# EFR32MG24A110F1024IM48 register map
Vendor: Silicon Labs; Series: EFR32; File version: B
Registers are 32-bit, read-write, reset 0x0 unless marked. A register's access mark holds for its fields unless they carry their own. Offsets are from the block's base; [hi:lo] are bit positions; {n}, {i} and the like mark numbered series; 'fields as' and 'values as' point back to an identical list.

## MODEM_S (part 1 of 2) — MODEM_S Registers
Base 0xA8014000
Same registers: MODEM_NS 0xB8014000
0x00 IPVERSION ro reset 0x3
0x04 EN
  [0] EN — Enable peripheral clock to this module
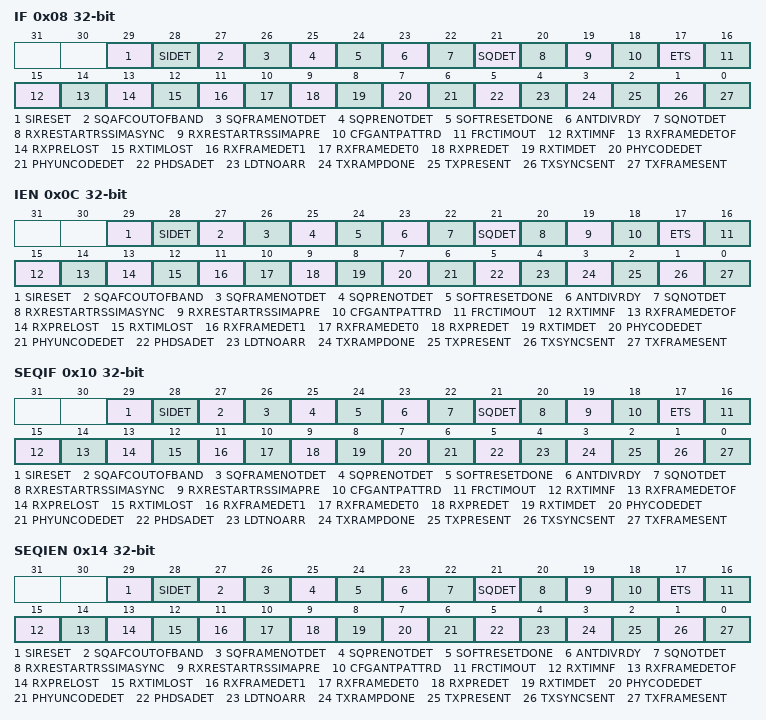
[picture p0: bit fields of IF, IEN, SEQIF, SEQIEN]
0x08 IF
  [29] SIRESET — Signal identifier reset
  [28] SIDET — Signal identified
  [27] SQAFCOUTOFBAND
  [26] SQFRAMENOTDET — SQ Not Detect
  [25] SQPRENOTDET — SQ Not Detect
  [24] SOFTRESETDONE
  [23] ANTDIVRDY — RSSI and CORR data Ready
  [22] SQNOTDET — SQ Not Detect
  [21] SQDET — SQ Detect
  [20] RXRESTARTRSSIMASYNC — RX restart using RSSI MA filter
  [19] RXRESTARTRSSIMAPRE — RX restart using RSSI MA filter
  [18] CFGANTPATTRD — cfg
  [17] ETS — Early Time Stamp detect
  [16] FRCTIMOUT — DEMOD-FRC req/ack timeout
  [15] RXTIMNF — Timing not found
  [14] RXFRAMEDETOF — Frame detection overflow
  [13] RXPRELOST — Preamble lost
  [12] RXTIMLOST — Timing lost
  [11] RXFRAMEDET1 — Frame with sync-word 1 detected
  [10] RXFRAMEDET0 — Frame with sync-word 0 detected
  [9] RXPREDET — Preamble detected
  [8] RXTIMDET — Timing detected
  [7] PHYCODEDET — CONCURRENT CODED PHY DET
  [6] PHYUNCODEDET — CONCURRENT UNCODED PHY DET
  [5] PHDSADET — PHASE DSA DETECT
  [4] LDTNOARR — No signal Detected in LDT
  [3] TXRAMPDONE — Mod ramper idle
  [2] TXPRESENT — Preamble sent
  [1] TXSYNCSENT — Sync word sent
  [0] TXFRAMESENT — Frame sent
0x0C IEN
  [29] SIRESET — Signal identifier reset
  [28] SIDET — Signal Identified
  [27] SQAFCOUTOFBAND
  [26] SQFRAMENOTDET — SQ Not Detected
  [25] SQPRENOTDET — SQ Not Detected
  [24] SOFTRESETDONE
  [23] ANTDIVRDY — RSSI and CORR data Ready
  [22] SQNOTDET — SQ Not Detected
  [21] SQDET — SQ Detected
  [20] RXRESTARTRSSIMASYNC — RX restart using RSSI MA filter
  [19] RXRESTARTRSSIMAPRE — RX restart using RSSI MA filter
  [18] CFGANTPATTRD
  [17] ETS — Early Time Stamp detect
  [16] FRCTIMOUT — DEMOD-FRC req/ack timeout
  [15] RXTIMNF — Timing not found
  [14] RXFRAMEDETOF — Frame detection overflow
  [13] RXPRELOST — Preamble lost
  [12] RXTIMLOST — Timing lost
  [11] RXFRAMEDET1 — Frame with sync-word 1 detected
  [10] RXFRAMEDET0 — Frame with sync-word 0 detected
  [9] RXPREDET — Preamble detected
  [8] RXTIMDET — Timing detected
  [7] PHYCODEDET — CONCURRENT CODED PHY DET
  [6] PHYUNCODEDET — CONCURRENT UNCODED PHY DET
  [5] PHDSADET — PHASE DSA DETECT
  [4] LDTNOARR — No signal Detected in LDT
  [3] TXRAMPDONE — Mod ramper idle
  [2] TXPRESENT — Preamble sent
  [1] TXSYNCSENT — Sync word sent
  [0] TXFRAMESENT — Frame sent
0x10 SEQIF
  [29] SIRESET — Signal identifier reset
  [28] SIDET — Signal identified
  [27] SQAFCOUTOFBAND
  [26] SQFRAMENOTDET — SQ NOT Detected
  [25] SQPRENOTDET — SQ NOT Detected
  [24] SOFTRESETDONE
  [23] ANTDIVRDY — RSSI and CORR data Ready
  [22] SQNOTDET — SQ NOT Detected
  [21] SQDET — SQ Detected
  [20] RXRESTARTRSSIMASYNC — RX restart using RSSI MA filter
  [19] RXRESTARTRSSIMAPRE — RX restart using RSSI MA filter
  [18] CFGANTPATTRD
  [17] ETS — Early timestamp
  [16] FRCTIMOUT — DEMOD-FRC req/ack timeout
  [15] RXTIMNF — Timing not found
  [14] RXFRAMEDETOF — Frame detection overflow
  [13] RXPRELOST — Preamble lost
  [12] RXTIMLOST — Timing lost
  [11] RXFRAMEDET1 — Frame with sync-word 1 detected
  [10] RXFRAMEDET0 — Frame with sync-word 0 detected
  [9] RXPREDET — Preamble detected
  [8] RXTIMDET — Timing detected
  [7] PHYCODEDET — CONCURRENT CODED PHY DET
  [6] PHYUNCODEDET — CONCURRENT UNCODED PHY DET
  [5] PHDSADET — PHASE DSA DETECT
  [4] LDTNOARR — No signal Detected in LDT
  [3] TXRAMPDONE — Mod ramper idle
  [2] TXPRESENT — Preamble sent
  [1] TXSYNCSENT — Sync word sent
  [0] TXFRAMESENT — Frame sent
0x14 SEQIEN
  [29] SIRESET — Signal identifier reset
  [28] SIDET — Signal Identified
  [27] SQAFCOUTOFBAND
  [26] SQFRAMENOTDET — SQ Not DET
  [25] SQPRENOTDET — SQ Not DET
  [24] SOFTRESETDONE
  [23] ANTDIVRDY — RSSI and CORR data Ready
  [22] SQNOTDET
  [21] SQDET
  [20] RXRESTARTRSSIMASYNC — RX restart using RSSI MA filter
  [19] RXRESTARTRSSIMAPRE — RX restart using RSSI MA filter
  [18] CFGANTPATTRD
  [17] ETS — Early time stamp
  [16] FRCTIMOUT — DEMOD-FRC req/ack timeout
  [15] RXTIMNF — Timing not found
  [14] RXFRAMEDETOF — Frame detection overflow
  [13] RXPRELOST — Preamble lost
  [12] RXTIMLOST — Timing lost
  [11] RXFRAMEDET1 — Frame with sync-word 1 detected
  [10] RXFRAMEDET0 — Frame with sync-word 0 detected
  [9] RXPREDET — Preamble detected
  [8] RXTIMDET — Timing detected
  [7] PHYCODEDET — CONCURRENT CODED PHY DET
  [6] PHYUNCODEDET — CONCURRENT UNCODED PHY DET
  [5] PHDSADET — PHASE DSA DETECT
  [4] LDTNOARR — No signal Detected in LDT
  [3] TXRAMPDONE — Mod ramper idle
  [2] TXPRESENT — Preamble sent
  [1] TXSYNCSENT — Sync word sent
  [0] TXFRAMESENT — Frame sent
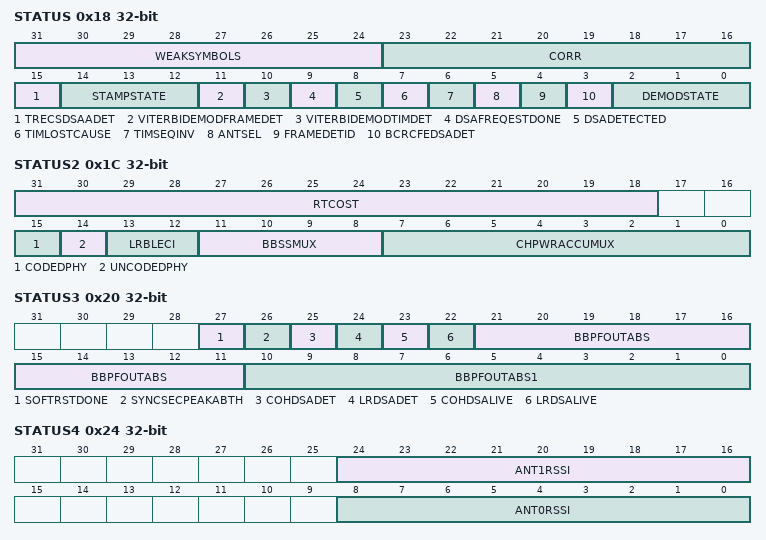
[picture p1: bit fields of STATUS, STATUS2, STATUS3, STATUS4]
0x18 STATUS ro
  [31:24] WEAKSYMBOLS
  [23:16] CORR — Correlation
  [15] TRECSDSAADET — TRECS DSA DETECTION
  [14:12] STAMPSTATE — BLE Viterbi Demod Timing Stamp
  [11] VITERBIDEMODFRAMEDET — Viterbi Demod frame detected
  [10] VITERBIDEMODTIMDET — Viterbi Demod timing detected
  [9] DSAFREQESTDONE — DSA frequency estimation complete
  [8] DSADETECTED — PHASE-DSA detected
  [7] TIMLOSTCAUSE — Timing Lost Cause
    0=LOWCORR (Timing lost during Preamble Search or due to low correlation value during Frame Search.); 1=TIMEOUT (Timing lost due to incorrect symbols detected during Frame Search.)
  [6] TIMSEQINV — Timing Sequence Inverted
  [5] ANTSEL — Selected Antenna
    0=ANTENNA0 (Antenna 0 is selected (ANT0 = 1 and ANT1 = 0).); 1=ANTENNA1 (Antenna 1 is selected (ANT0 = 0 and ANT1 = 1).)
  [4] FRAMEDETID — Frame Detected ID
    0=FRAMEDET0 (Last frame was detected with sync word defined in SYNC0.); 1=FRAMEDET1 (Last frame was detected with sync word defined in SYNC1.)
  [3] BCRCFEDSADET — BCR CFE DSA DETECTION
  [2:0] DEMODSTATE
    0=OFF (Off state); 1=TIMINGSEARCH; 2=PRESEARCH (Preamble search); 3=FRAMESEARCH; 4=RXFRAME (Payload Detection); 5=FRAMEDETMODE0 (Timing search with sliding window (FDM0))
0x1C STATUS2 ro
  [31:18] RTCOST — phase demod real time cost
  [15] CODEDPHY — CODED PHY DET
  [14] UNCODEDPHY — UNCODED PHY DET
  [13:12] LRBLECI — RXed packet's LR BLE coding indicator
    0=LR125k (FEC block 2 coded using C=8, 125kbps); 1=LR500k (FEC block 2 coded using C=2, 500kbps)
  [11:8] BBSSMUX — Actual Baseband Signal Selection
  [7:0] CHPWRACCUMUX — Channel power
0x20 STATUS3 ro
  [27] SOFTRSTDONE — Soft reset done
  [26] SYNCSECPEAKABTH — SYNC second peak above threshold
  [25] COHDSADET — DSA prefilter above CDTH
  [24] LRDSADET — DSA prefilter above LRSPIKETHD
  [23] COHDSALIVE — COHDSA Prefilter above CDTH
  [22] LRDSALIVE — BLRDSA Prefilter above LRSPIKETHD
  [21:11] BBPFOUTABS — Pre-filter Correlation Output for BLR
  [10:0] BBPFOUTABS1 — Pre-filter Correlation Output
0x24 STATUS4 ro
  [24:16] ANT1RSSI — ANT1 RSSI value
  [8:0] ANT0RSSI — ANT0 RSSI value
0x28 STATUS5 ro
  [8:0] RXRESTARTMAFLTDOUT — RSSI MA filter output value
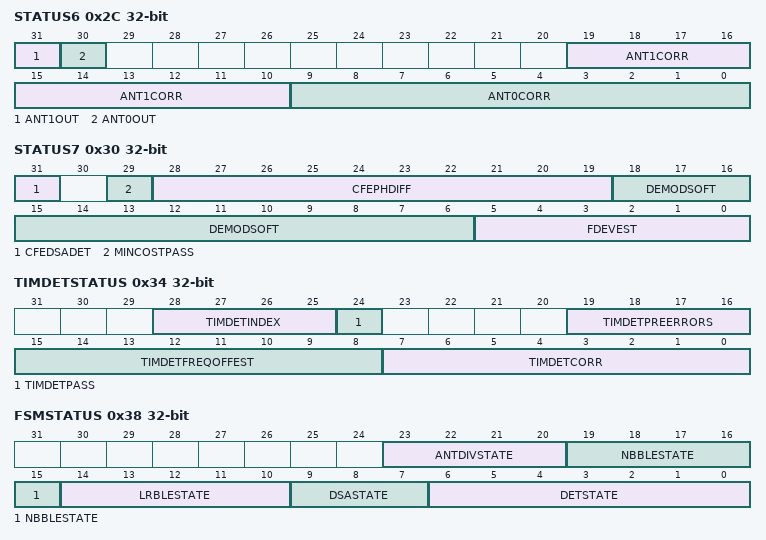
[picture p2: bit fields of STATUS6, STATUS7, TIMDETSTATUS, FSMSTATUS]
0x2C STATUS6 ro
  [31] ANT1OUT — ANT1 OUTPUT
  [30] ANT0OUT — ANT0 OUTPUT
  [19:10] ANT1CORR — ANT1 Correlation value
  [9:0] ANT0CORR — ANT0 Correlation value
0x30 STATUS7 ro
  [31] CFEDSADET — CFE-based DSA Detection
  [29] MINCOSTPASS — Min.COST Threshold Pass
  [28:19] CFEPHDIFF — CEF PHASE DIFF INPUT
  [18:6] DEMODSOFT — PHASE DEMOD Soft code
  [5:0] FDEVEST — Frequency Deviation Error Estimation
0x34 TIMDETSTATUS ro
  [28:25] TIMDETINDEX — Timing detection index
  [24] TIMDETPASS — Timing detection pass
  [19:16] TIMDETPREERRORS — Preamble errors
  [15:8] TIMDETFREQOFFEST — Frequency offset estimate
  [7:0] TIMDETCORR — Correlation value
0x38 FSMSTATUS ro
  [23:20] ANTDIVSTATE — Antenna diversity control state
    0=IDLE (Idle state); 1=FIRST_ANT0 (First ANT0 selection); 2=FIRST_ANT1 (First ANT1 selection); 3=TIMSEARCH_ANT0 (Timing search on ANT0); 4=TIMSEARCH_ANT1 (Timing search on ANT1); 5=TIMDET_ANT0 (Check ANT1 after timing detecton ANT0); 6=TIMDET_ANT1 (Check ANT0 after timing detecton ANT1); 7=EVALUATE (Evaluate and select better antenna); 8=TIMSEARCH_SELECTED (Searching on better antenna); 9=TIMDET_SELECTED (Selected better antenna); 10=REPEAT_ANT0; 11=REPEAT_ANT1; 15=MANUAL (Manual mode)
  [19:15] NBBLESTATE — Demodulator Narrow-band BLE FSM state
    0=IDLE (IDLE state); 1=VTINITI; 2=ADDRNXT; 3=INICOST; 4=CALCCOST; 5=INITALACQU; 6=INITALCOSTCALC; 7=MINCOSTCALC; 8=FREQACQU; 9=FREQACQUDONE; 10=TIMINGACQUEARLY; 11=TIMINGACQUCURR; 12=TIMINGACQULATE; 13=TIMINGACQUDONE; 14=VIRTBIINIT0; 15=VIRTBIINIT1; 16=VIRTBIRXSYNC; 17=VIRTBIRXPAYLOAD; 18=HARDRXSYNC; 19=HARDXPAYLOAD (HARD_RXPAYLOAD); 20=TRACKFREQ; 21=TRACKTIMEARLY; 22=TRACKTIMCURR; 23=TRACKTIMLATE; 24=TRACKDONE; 25=TRACKDECISION; 26=STOP; 27=WAITACK; 28=DEBUG
  [14:10] LRBLESTATE — Demodulator long-range BLE FSM state
    0=IDLE (IDLE state); 1=CLEANUP; 2=CORRCOE; 3=WAITLRDSA; 4=MAXCORR; 5=WAITRDY; 6=FEC1DATA; 7=FEC1ACK; 8=PAUSE; 9=FEC2DATA; 10=FEC2ACK; 11=TRACKCUR; 12=TRACKEAR; 13=TRACKLAT; 14=TRACKDONE; 15=TDECISION; 16=STOP
  [9:7] DSASTATE — Demodulator DSA FSM state
    0=IDLE (IDLE state); 1=ARRIVALCHK (Arrival Check); 2=STATUSCHK (Status Check); 3=SAMPPW; 4=WAITPWRUP; 5=WAITDSALO; 6=WAITABORT; 7=STOP
  [6:0] DETSTATE — Detection FSM state
    0=OFF (Off state); 10=TIMINGSEARCH; 20=PRESEARCH (Preamble search); 30=FRAMESEARCH; 40=RXFRAME (Payload Detection); 50=FRAMEDETMODE0 (Timing search with sliding window (FDM0))
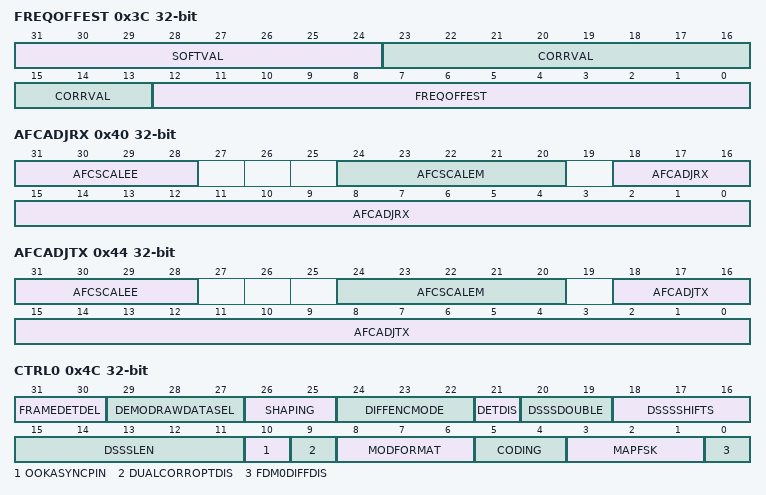
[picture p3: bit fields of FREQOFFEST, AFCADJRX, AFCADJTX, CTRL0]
0x3C FREQOFFEST ro
  [31:24] SOFTVAL — Soft detection value
  [23:13] CORRVAL — Correlation value
  [12:0] FREQOFFEST — Frequency offset estimate
0x40 AFCADJRX
  [31:28] AFCSCALEE — AFC scaling exponent
  [24:20] AFCSCALEM — AFC scaling mantissa
  [18:0] AFCADJRX ro — AFC adjustment for RX
0x44 AFCADJTX
  [31:28] AFCSCALEE — AFC scaling exponent
  [24:20] AFCSCALEM — AFC scaling mantissa
  [18:0] AFCADJTX ro — AFC adjustment for TX
0x48 MIXCTRL
  [4] DIGIQSWAPEN — Digital I/Q swap enable
0x4C CTRL0
  [31:30] FRAMEDETDEL — FRAMEDET delay
    0=DEL0 (No delay); 1=DEL8 (8 baud delay); 2=DEL16 (16 baud delay); 3=DEL32 (32 baud delay)
  [29:27] DEMODRAWDATASEL — Demod raw data select
    0=DIS (Disabled.); 1=ENTROPY (1-bit entropy source extracted from the RF receive chain, to be used for random number generation.); 2=ADC (2 * 3-bit I and Q ADC data.); 3=FILTLSB (2 * 16-bit I and Q channel filtered data downmixed to zero-IF. The receive signal chain has 19 bits dynamic range at this point, and the FILTLSB setting outputs the 16 least significant bits (with saturation).); 4=FILTMSB (2 * 16-bit I and Q channel filtered data downmixed to zero-IF. The receive signal chain has 19 bits dynamic range at this point, and the FILTMSB setting outputs the 16 most significant bits (with truncation).); 5=FILTFULL (2 * 19-bit I and Q channel filtered data downmixed to zero-IF. The FILTFULL option will output all 19 bits of dynamic range, sign extended to 32 bits.); 6=FREQ (8-bit received frequency data (or logarithmic amplitude for ASK/OOK).); 7=DEMOD (8-bit demodulated data (freq/amp/phase). When coherent detection is enabled, only the in-phase component is selected.)
  [26:25] SHAPING — Shaping filter
    0=DISABLED (Filter disabled.); 1=ODDLENGTH (Filter has odd length. Filter uses coefficients 0,1,2,3,4,5,6,7,8,7,6,5,4,3,2,1,0.); 2=EVENLENGTH (Filter has even length. Filter uses coefficients 0,1,2,3,4,5,6,7,7,6,5,4,3,2,1,0.); 3=ASYMMETRIC (Filter has asymmetrical coefficients. Filter uses coefficients 0,1,2,3,4,5,6,7.)
  [24:22] DIFFENCMODE — Differential encoding mode
    0=DIS (Differential Encoding is disabled.); 1=RR0 (Transmit the XOR-ed value of the Raw symbol and the last Raw symbol. Initial Raw symbol is 0.); 2=RE0 (Transmit the XOR-ed value of the Raw symbol and the last Encoded symbol. Initial Encoded symbol is 0.); 3=RR1 (Transmit the XOR-ed value of the Raw symbol and the last Raw symbol. Initial Raw symbol is 1.); 4=RE1 (Transmit the XOR-ed value of the Raw symbol and the last Encoded symbol. Initial Encoded symbol is 1.)
  [21] DETDIS — Detection disable
  [20:19] DSSSDOUBLE
    0=DIS (Doubling is disabled.); 1=INV (Doubling is enabled by using inverted symbols.); 2=CONJ (Doubling is enabled by using complex conjugated symbols.)
  [18:16] DSSSSHIFTS
    0=NOSHIFT (No symbols are defined by shifting.); 1=SHIFT1 (Next symbol generated by 1 cyclic shift.); 2=SHIFT2 (Next symbol generated by 2 cyclic shifts.); 3=SHIFT4 (Next symbol generated by 4 cyclic shifts.); 4=SHIFT8 (Next symbol generated by 8 cyclic shifts.); 5=SHIFT16 (Next symbol generated by 16 cyclic shifts.)
  [15:11] DSSSLEN — DSSS length
  [10] OOKASYNCPIN — OOK asynchronous pin mode
  [9] DUALCORROPTDIS — Dual Correlation Optimization Disable
  [8:6] MODFORMAT — Modulation format
    0=FSK2 (Frequency Shift Keying with 2 symbols); 1=FSK4 (Frequency Shift Keying with 4 symbols); 2=BPSK (Binary Phase Shift Keying); 3=DBPSK (Differentially encoded Binary Phase Shift Keying); 4=OQPSK (Half Sine Shaped Offset Quadrature Phase Shift Keying); 5=MSK (Minimum Shift Keying); 6=OOKASK (On Off Keying and Amplitude Shift Keying)
  [5:4] CODING — Symbol coding
    0=NRZ (Non Return to Zero); 1=MANCHESTER (Manchester Coding); 2=DSSS (Direct Sequence Spread Spectrum); 3=LINECODE (Line code. Maps 0 to 0011 symbol and 1 to 1100 symbols)
  [3:1] MAPFSK — Mapping of FSK symbols
    0=MAP0 (4FSK: Symbol 11, 10, 00, 01 for decreasing frequency. 2FSK/MSK/ASK/OOK: Symbol 1 is high/positive frequency or high amplitude, symbol 0 is low/negative frequency or low amplitude.); 1=MAP1 (4FSK: Symbol 01, 00, 10, 11 for decreasing frequency. 2FSK/MSK/ASK/OOK: Symbol 0 is high/negative frequency or high amplitude, symbol 1 is low/negative frequency or low amplitude.); 2=MAP2 (4FSK: Symbol 10, 11, 01, 00 for decreasing frequency. 2FSK/MSK/ASK/OOK: Undefined.); 3=MAP3 (4FSK: Symbol 00, 01, 11, 10 for decreasing frequency. 2FSK/MSK/ASK/OOK: Undefined.); 4=MAP4 (4FSK: Symbol 11, 01, 00, 10 for decreasing frequency. 2FSK/MSK/ASK/OOK: Undefined.); 5=MAP5 (4FSK: Symbol 10, 00, 01, 11 for decreasing frequency. 2FSK/MSK/ASK/OOK: Undefined.); 6=MAP6 (4FSK: Symbol 01, 11, 10, 00 for decreasing frequency. 2FSK/MSK/ASK/OOK: Undefined.); 7=MAP7 (4FSK: Symbol 00, 10, 11, 01 for decreasing frequency. 2FSK/MSK/ASK/OOK: Undefined.)
  [0] FDM0DIFFDIS — Frame Detection Mode 0 disable
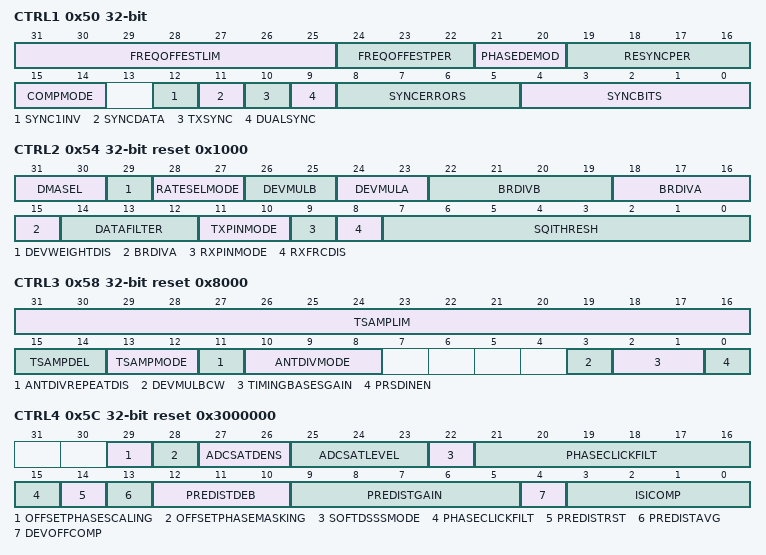
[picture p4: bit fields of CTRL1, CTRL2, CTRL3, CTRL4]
0x50 CTRL1
  [31:25] FREQOFFESTLIM — Frequency offset limit
  [24:22] FREQOFFESTPER — Frequency offset estimation period
  [21:20] PHASEDEMOD — Phase demodulation
    0=BDD (Bit Differential Detection.); 1=MBDD (Multibit Differential Detection.); 2=COH (Coherent Detection.)
  [19:16] RESYNCPER — Resync period
  [15:14] COMPMODE — Compensation mode
    0=DIS (Compensation is disabled.); 1=PRELOCK (Compensation locks when preamble is detected.); 2=FRAMELOCK (Compensation locks when frame is detected.); 3=NOLOCK (Compensation is always running)
  [12] SYNC1INV — SYNC1 invert.
  [11] SYNCDATA
    0=DISABLED (SYNC is not part of transmit payload. Modulator adds SYNC in transmit.); 1=ENABLED (SYNC is part of transmit payload. Modulator does not add SYNC in transmit.)
  [10] TXSYNC — Transmit sync word.
    0=SYNC0 (Modulator transmits SYNC0.); 1=SYNC1 (Modulator transmits SYNC1.)
  [9] DUALSYNC — Dual sync words.
    0=DISABLED (Demodulator only searches for SYNC0.); 1=ENABLED (Demodulator searches for SYNC0 and SYNC1 in parallel.)
  [8:5] SYNCERRORS — Maximum number of sync errors
  [4:0] SYNCBITS — Number of sync-word bits
0x54 CTRL2 reset 0x1000
  [31:30] DMASEL — DMA select.
    0=SOFT (SOFTVAL field); 1=CORR (CORRVAL field); 2=FREQOFFEST; 3=POE
  [29] DEVWEIGHTDIS — Deviation weighting disable.
  [28:27] RATESELMODE — Rate select mode
    0=NOCHANGE (No rate change. BRDIVA/DEVMULA is used for entire frame.); 1=PAYLOAD (Change rate for payload. BRDIVA/DEVMULA is used for header and BRDIVB/DEVMULB is used for payload.); 2=FRC (FRC selects between BRDIVA/DEVMULA and BRDIVB/DEVMULB for each symbol in the payload. Header uses BRDIVA/DEVMULA.); 3=SYNC (The configured/detected syncword decides the settings used for the payload. SYNC0 uses BRDIVA/DEVMULA and SYNC1 uses BRDIVB/DEVMULB. Header uses BRDIVA/DEVMULA.)
  [26:25] DEVMULB — Deviation multiplication factor B
  [24:23] DEVMULA — Deviation multiplication factor A
  [22:19] BRDIVB — Baudrate division factor B
  [18:15] BRDIVA — Baudrate division factor A
  [14:12] DATAFILTER
    0=DISABLED (Datafilter disabled); 1=SHORT (Short datafilter enabled. 2*RXBRFRAC should be more than 3.); 2=MEDIUM (Medium datafilter enabled. 2*RXBRFRAC should be more than 4.); 3=LONG (Long datafilter enabled. 2*RXBRFRAC should be more than 5.); {v}=LEN{v+2} (Datafilter with length {v+2} enabled. 2*RXBRFRAC should be more than {v+2}.) (v=4..7)
  [11:10] TXPINMODE — Transmit pin mode
    0=OFF (Pinmode is turned off. Data is gathered from FRC. DOUT/DCLK clocks out transmitted data.); 1=MFM (Pinmode is turned off. Multi-Level FM Data is gathered from FRC. No support for frame handling nor coding); 2=ASYNCHRONOUS (DIN/PRS controls transmitted baud directly. DCLK is set to 0. No support for frame handling nor coding. Only 2-FSK and OOK/ASK can be used.); 3=SYNCHRONOUS (DIN/PRS is sampled on the rising edge of DCLK and used as payload. Frame handling and coding is supported. Only setups with 1 bit per symbol is supported.)
  [9] RXPINMODE — Receive pin mode
    0=SYNCHRONOUS (Detected payload bits are clocked out on DOUT. Only setups with 1 bit per symbol are supported.); 1=ASYNCHRONOUS (DOUT is continuously providing the sign of the detected frequency deviation before offset compensation. Only 2/4-FSK is supported.)
  [8] RXFRCDIS — Receive FRC disable
  [7:0] SQITHRESH — Signal Quality Indicator threshold
0x58 CTRL3 reset 0x8000
  [31:16] TSAMPLIM — Timing Search Amplitude limit
  [15:14] TSAMPDEL — Timing Search Amplitude delay
  [13:12] TSAMPMODE — Timing Search Amplitude Mode
    0=OFF (Amplitude is not used during timing search.); 1=ON (Timing detection is disabled for windows where at least one sample is below limit set by TSAMPLIM.); 2=DIFF (Timing detection is disabled for windows where the difference between samples is higher than the limit set by TSAMPLIM.)
  [11] ANTDIVREPEATDIS — Antenna diversity repeat disable
  [10:8] ANTDIVMODE — Antenna Diversity mode
    0=ANTENNA0 (Antenna 0 (ANT0=1, ANT1=0) is used. It is used to control the anntenna manually no matter which demodulator is selected .); 1=ANTENNA1 (Antenna 1 (ANT0=0, ANT1=1) is used.It is used to control the anntenna manually no matter which demodulator is selected .); 2=ANTSELFIRST (Select-First algorithm. It is used for for coh-demod and legacy demod only.); 3=ANTSELCORR (Select-Best algorithm based on correlation value.It is used for for coh-demod and legacy demod only.); 4=ANTSELRSSI (Select-Best algorithm based on RSSI value.It is used for for coh-demod and legacy demod only.); 5=PHDEMODANTDIV (Select PHASE Demod ANT-DIV algorithm)
  [3] DEVMULBCW — Deviatiion Factor B CW Mode
  [2:1] TIMINGBASESGAIN
  [0] PRSDINEN — DIN PRS enable
0x5C CTRL4 reset 0x3000000
  [29] OFFSETPHASESCALING
  [28] OFFSETPHASEMASKING
  [27:26] ADCSATDENS — ADC Saturation Density setting
  [25:23] ADCSATLEVEL — ADC Saturation Level setting
    0=CONS1 (AGC enters fast loop after first saturation sample.); 1=CONS2 (2 saturation samples required before AGC enters fast loop.); 2=CONS4 (4 saturation samples required before AGC enters fast loop.); 3=CONS8 (8 saturation samples required before AGC enters fast loop.); 4=CONS16 (16 saturation samples required before AGC enters fast loop.); 5=CONS32 (32 saturation samples required before AGC enters fast loop.); 6=CONS64 (64 saturation samples required before AGC enters fast loop.)
  [22] SOFTDSSSMODE
    0=CORR0INV (Soft value is inverted value of symbol-0 correlation value.); 1=CORRDIFF (Soft value is difference between correlation values for symbol-0 and symbol-1.)
  [21:15] PHASECLICKFILT — Phase click filter
  [14] PREDISTRST — Predistortion Reset
  [13] PREDISTAVG — Predistortion Average
    0=AVG8 (Average over 8 samples.); 1=AVG16 (Average over 16 samples.)
  [12:10] PREDISTDEB — Predistortion debounce
  [9:5] PREDISTGAIN — Predistortion gain
  [4] DEVOFFCOMP — Deviation offset compensation
  [3:0] ISICOMP — Inter Symbol Interference compensation
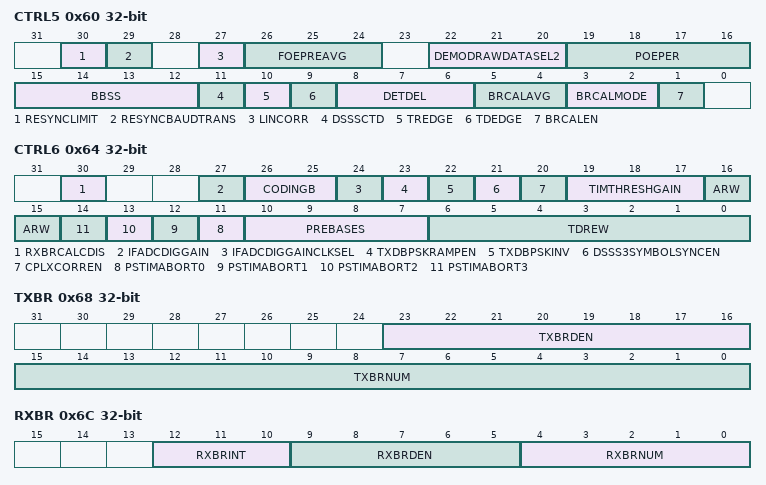
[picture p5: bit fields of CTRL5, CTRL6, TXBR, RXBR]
0x60 CTRL5
  [30] RESYNCLIMIT — Resynchronization Limit
    0=HALF (Adjust timing if accumulated timing is higher/lower than RESYNCPER/2.); 1=ALWAYS (Adjust timing if accumulated timing is non-zero.)
  [29] RESYNCBAUDTRANS — Resynchronization Baud Transitions
  [27] LINCORR — Linear Correlation
  [26:24] FOEPREAVG — Frequency Offset Estimate Pre-Averaging
  [22:20] DEMODRAWDATASEL2 — Demod raw data select 2
    0=DIS (Disabled.); 1=COH (Coherent demod 5-bit I and Q input data, 10-bit I and Q data after FOE/POE.); 2=CORR (4-bit max_corr_index and 17-bit max_corr .); 3=CHPW (8-bit channel power and 4-bit BBSSMUX); 4=BBPF (11-bit pre-filter correlation output for BLR and 11-bit pre-filter correlation output for COH demod); 5=FSM (5-bit Narrow-band BLE FSM state, 5-bit Long-range BLE FSM state, 3-bit DSA FSM state, 7-bit Detection FSM State. Captured each time state changes); 6=HADM (Packed 32-bit words containing the results of HADM SQTE steps)
  [19:16] POEPER — Phase Offset Estimation Period
  [15:12] BBSS — Baseband Signal Selection
  [11] DSSSCTD — DSSS Correlation Threshold Disable
  [10] TREDGE — Timing resynchronization edge mode
  [9] TDEDGE — Timing detection edge mode
  [8:6] DETDEL — Detection delay
  [5:4] BRCALAVG — Baudrate calibration averaging
  [3:2] BRCALMODE — Baudrate calibration mode
    0=PEAK (Measure period between peaks in demodulated signal. This mode can give false peaks for high oversampling ratios without sufficient datafiltering.); 1=ZERO (Measure period between zero-crossings in demodulated signal. This mode can miss zero-crossings for high frequency offsets.); 2=PEAKZERO (Combine peak-period and zero-crossing periods. This mode gives best accuracy, but includes weaknesses from both PEAK and ZERO modes.)
  [1] BRCALEN — Baudrate calibration enable
0x64 CTRL6
  [30] RXBRCALCDIS — RX Baudrate Calculation Disable
  [27] IFADCDIGGAIN — IFADC Output Dig Gain Select
  [26:25] CODINGB — Coding format
    values as CTRL0.CODING
  [24] IFADCDIGGAINCLKSEL — IFADC Output Dig Gain Clock Select
  [23] TXDBPSKRAMPEN — TX DBPSK PA Ramp Enable
  [22] TXDBPSKINV — TX DBPSK modulation encode invert
  [21] DSSS3SYMBOLSYNCEN — Enable three symbol sync detection
  [20] CPLXCORREN — Enable Complex Correlation
  [19:17] TIMTHRESHGAIN — Timing Threshold Gain
  [16:15] ARW — Allow Received Window
    0=SMALLWND (Allow received windows when window size is less than half the RAM size.); 1=ALWAYS (Always allow received windows.); 2=NEVER (Never allow received windows.); 3=PSABORT (Allow received windows right after PSTIMABORTn tests have aborted timing and coherent detection is enabled, or when window size is less than half the RAM size.)
  [n+11] PSTIMABORT{n} (n=0..3) — Preamble Search Timing Abort Criteria {n}
  [10:7] PREBASES — Preamble Bases
  [6:0] TDREW — Timing Detection Rewind
0x68 TXBR
  [23:16] TXBRDEN — Transmit baudrate denominator
  [15:0] TXBRNUM — Transmit baudrate numerator
0x6C RXBR
  [12:10] RXBRINT — Receive baudrate integer
  [9:5] RXBRDEN — Receive baudrate denominator
  [4:0] RXBRNUM — Receive baudrate numerator
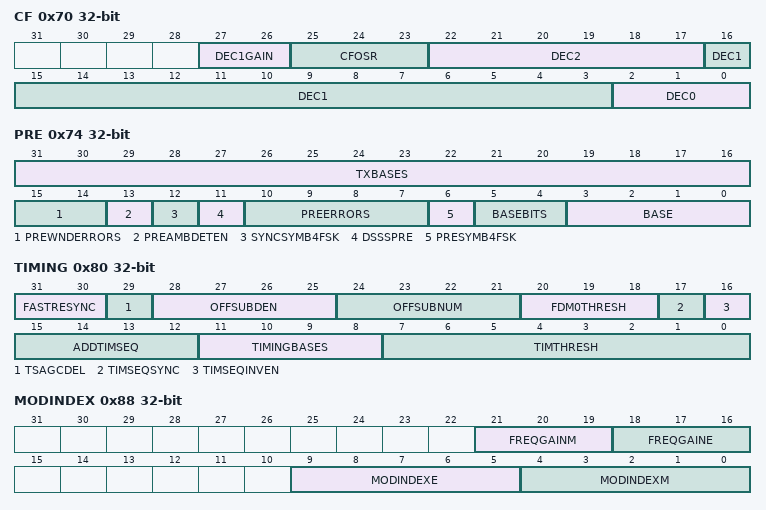
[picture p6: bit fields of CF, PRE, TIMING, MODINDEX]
0x70 CF
  [27:26] DEC1GAIN — Second decimation filter gain
    0=ADD0 (No additional gain. Suggested setting for BW higher than 1kHz); 1=ADD6 (6 dB additional gain. Suggested setting for BW between 250 Hz and 1 kHz); 2=ADD12 (12 dB additional gain. Suggested setting for BW less than 250 Hz)
  [25:23] CFOSR — Center Frequency Oversampling Ratio
    0=CF7 (Oversampling ratio = 7); 1=CF8 (Oversampling ratio = 8); 2=CF12 (Oversampling ratio = 12); 3=CF16 (Oversampling ratio = 16); 4=CF32 (Oversampling ratio = 32); 5=CF0 (Center frequency set to 0)
  [22:17] DEC2 — Third decimation
  [16:3] DEC1 — Second decimation
  [2:0] DEC0 — First decimation
    0=DF3 (Decimation Factor 0 = 3. Cutoff 0.050 * f<subscript>HFXO</subscript>.); 1=DF4WIDE (Decimation Factor 0 = 4. Cutoff 0.069 * f<subscript>HFXO</subscript>.); 2=DF4NARROW (Decimation Factor 0 = 4. Cutoff 0.037 * f<subscript>HFXO</subscript>.); 3=DF8WIDE (Decimation Factor 0 = 8. Cutoff 0.012 * f<subscript>HFXO</subscript>.); 4=DF8NARROW (Decimation Factor 0 = 8. Cutoff 0.005 * f<subscript>HFXO</subscript>.)
0x74 PRE
  [31:16] TXBASES
  [15:14] PREWNDERRORS — Preamble window errors
  [13] PREAMBDETEN — Binary bit preamble det enable
  [12] SYNCSYMB4FSK — Sync symbols 4FSK
    0=FSK2 (The syncword is 2FSK modulated. Each bit in SYNCn is encoded as a positive or negative deviation. The deviation is controlled by PRESYMB4FSK.); 1=FSK4 (The syncword is 4FSK modulated. Every two bits in SYNCn are encoded as a 4FSK symbol.)
  [11] DSSSPRE — DSSS preamble
  [10:7] PREERRORS — Preamble errors
  [6] PRESYMB4FSK — Preamble symbols 4-FSK
    0=OUTER (Symbols corresponding to +/- 3dev.); 1=INNER (Symbols corresponding to +/- dev.)
  [5:4] BASEBITS
  [3:0] BASE — Preamble base
0x78 SYNC0
  [31:0] SYNC0 — Sync-word 0
0x7C SYNC1
  [31:0] SYNC1 — Sync word 1
0x80 TIMING
  [31:30] FASTRESYNC — Fast timing resynchronization
    0=DIS (Disabled.); 1=PREDET (Allow fast resynchronization until preamble is detected.); 2=FRAMEDET (Allow fast resynchronization until frame is detected.)
  [29] TSAGCDEL — Timing Search AGC delay
  [28:25] OFFSUBDEN — Offset subperiod denominator
  [24:21] OFFSUBNUM — Offset subperiod numerator
  [20:18] FDM0THRESH — Frame Detection Mode 0 threshold
  [17] TIMSEQSYNC — Timing sequence part of sync-word
  [16] TIMSEQINVEN — Timing sequence inversion enable
  [15:12] ADDTIMSEQ — Additional timing sequences
  [11:8] TIMINGBASES
  [7:0] TIMTHRESH — Timing threshold
0x84 DSSS0
  [31:0] DSSS0 — DSSS symbol 0
0x88 MODINDEX
  [21:19] FREQGAINM — Frequency demodulation gain - mantissa
  [18:16] FREQGAINE — Frequency demodulation gain - exponent
  [9:5] MODINDEXE — Modulation index exponent.
  [4:0] MODINDEXM — Modulation index mantissa.
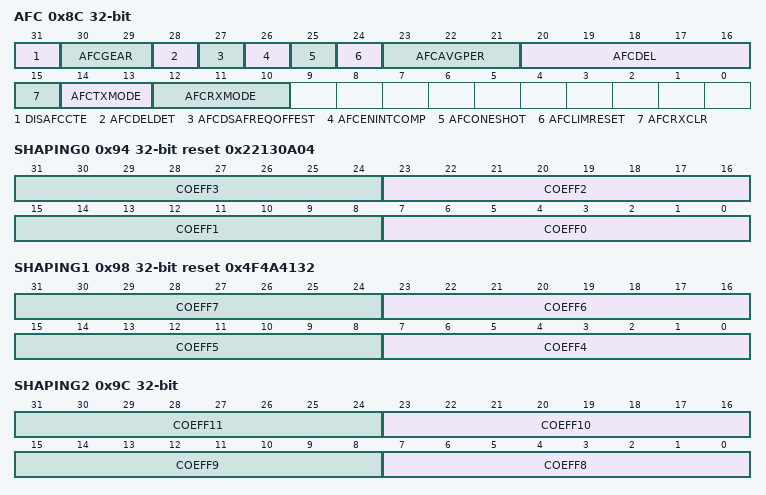
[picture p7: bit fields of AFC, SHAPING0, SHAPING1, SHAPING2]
0x8C AFC
  [31] DISAFCCTE — Disable AFC in AoX CTE
  [30:29] AFCGEAR
  [28] AFCDELDET — Delay Detection state machine
  [27] AFCDSAFREQOFFEST — Consider frequency offset estimation
  [26] AFCENINTCOMP — Internal frequency offset compensation
  [25] AFCONESHOT — AFC One-Shot feature
  [24] AFCLIMRESET — Reset AFCADJRX value
  [23:21] AFCAVGPER — AFC average period
  [20:16] AFCDEL — AFC delay
  [15] AFCRXCLR — AFCRX clear mode
  [14:13] AFCTXMODE
    0=DIS (Disabled.); 1=PRELOCK (AFCADJTX loaded from AFCADJRX when preamble is detected.); 2=FRAMELOCK (AFCADJTX loaded from AFCADJRX when frame is detected.)
  [12:10] AFCRXMODE
    0=DIS (Disabled.); 1=FREE (Free running. AFCADJRX constantly updated.); 2=FREEPRESTART (Free running. AFCADJRX not updated before preamble is detected.); 3=TIMLOCK (AFCADJRX locked when timing is detected.); 4=PRELOCK (AFCADJRX locked when preamble is detected.); 5=FRAMELOCK (AFCADJRX locked when frame is detected.); 6=FRAMELOCKPRESTART (AFCADJRX not updated before preamble is detected and locked when frame is detected.)
0x90 AFCADJLIM
  [17:0] AFCADJLIM — AFC adjustment limit
0x94 SHAPING0 reset 0x22130A04
  [8n+7:8n] COEFF{n} (n=0..3) — Shaping Coefficient {n}
0x98 SHAPING1 reset 0x4F4A4132
  [8n-25:8n-32] COEFF{n} (n=4..7) — Shaping Coefficient {n}
0x9C SHAPING2
  [8n-57:8n-64] COEFF{n} (n=8..11) — Shaping Coefficient {n}
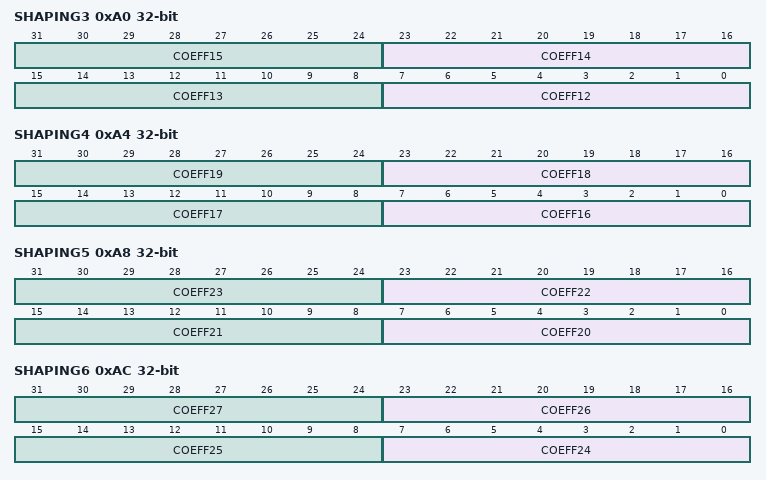
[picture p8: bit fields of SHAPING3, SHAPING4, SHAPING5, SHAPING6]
0xA0 SHAPING3
  [8n-89:8n-96] COEFF{n} (n=12..15) — Shaping Coefficient {n}
0xA4 SHAPING4
  [8n-121:8n-128] COEFF{n} (n=16..19) — Shaping Coefficient {n}
0xA8 SHAPING5
  [8n-153:8n-160] COEFF{n} (n=20..23) — Shaping Coefficient {n}
0xAC SHAPING6
  [8n-185:8n-192] COEFF{n} (n=24..27) — Shaping Coefficient {n}
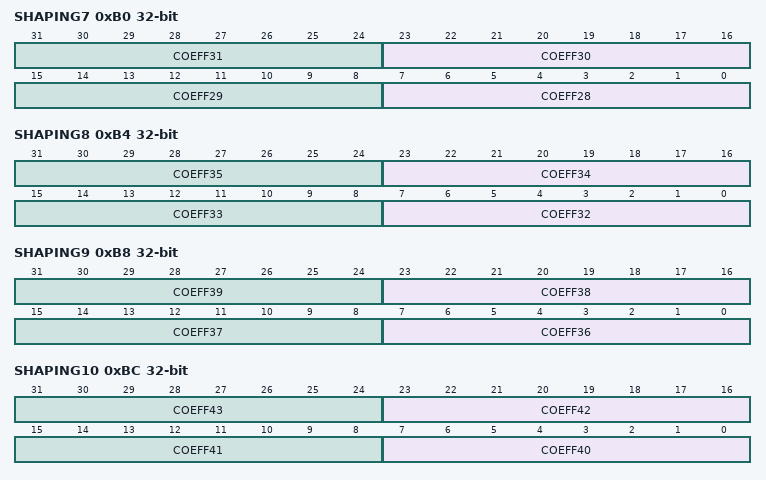
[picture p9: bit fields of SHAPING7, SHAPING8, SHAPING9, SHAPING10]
0xB0 SHAPING7
  [8n-217:8n-224] COEFF{n} (n=28..31) — Shaping Coefficient {n}
0xB4 SHAPING8
  [8n-249:8n-256] COEFF{n} (n=32..35) — Shaping Coefficient {n}
0xB8 SHAPING9
  [8n-281:8n-288] COEFF{n} (n=36..39) — Shaping Coefficient {n}
0xBC SHAPING10
  [8n-313:8n-320] COEFF{n} (n=40..43) — Shaping Coefficient {n}
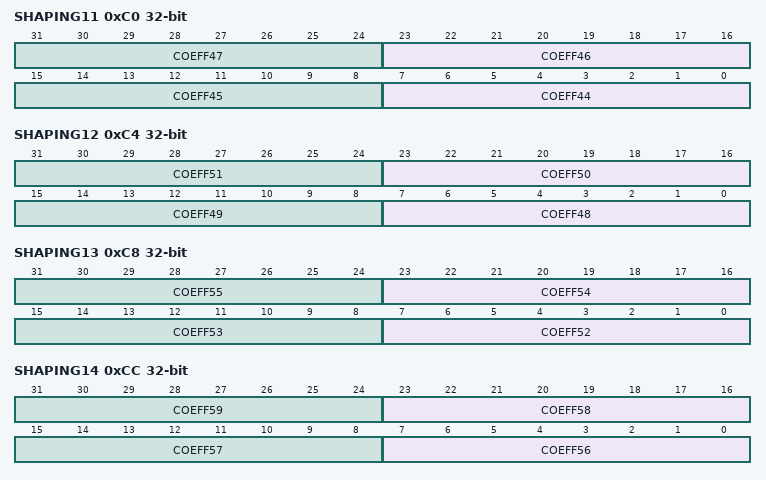
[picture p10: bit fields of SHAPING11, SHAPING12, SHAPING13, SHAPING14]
0xC0 SHAPING11
  [8n-345:8n-352] COEFF{n} (n=44..47) — Shaping Coefficient {n}
0xC4 SHAPING12
  [8n-377:8n-384] COEFF{n} (n=48..51) — Shaping Coefficient {n}
0xC8 SHAPING13
  [8n-409:8n-416] COEFF{n} (n=52..55) — Shaping Coefficient {n}
0xCC SHAPING14
  [8n-441:8n-448] COEFF{n} (n=56..59) — Shaping Coefficient {n}
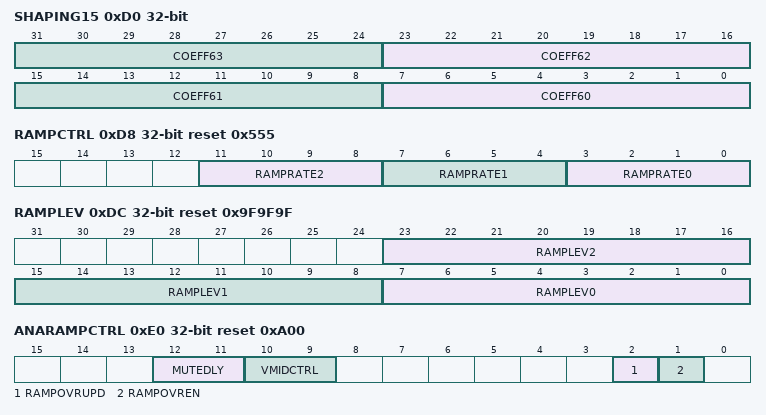
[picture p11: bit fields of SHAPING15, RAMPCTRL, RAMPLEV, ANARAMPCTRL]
0xD0 SHAPING15
  [8n-473:8n-480] COEFF{n} (n=60..63) — Shaping Coefficient {n}
0xD8 RAMPCTRL reset 0x555
  [11:8] RAMPRATE2, [7:4] RAMPRATE1, [3:0] RAMPRATE0
0xDC RAMPLEV reset 0x9F9F9F
  [23:16] RAMPLEV2 — Ramp level 2
  [15:8] RAMPLEV1 — Ramp level 1
  [7:0] RAMPLEV0 — Ramp level 0
0xE0 ANARAMPCTRL reset 0xA00
  [12:11] MUTEDLY — PA Analog Ramp mute delay
    0=TIME0US (Mute to ramp drv/odev delay set to 0us); 1=TIME0P5US (Mute to ramp drv/odev delay set to 0.5us); 2=TIME0P25US (Mute to ramp drv/odev delay set to 0.25us); 3=NOTUSED (Unused Mute to ramp drv/odev delay value)
  [10:9] VMIDCTRL — PA Analog Ramp VMID control
    0=OFF (en_xdrv_vmid always off); 1=MID (en_xdrv_vmid ramp_drv threshold set to midscale); 2=HIGH (en_xdrv_vmid ramp_drv threshold set to highest level); 3=ON (en_xdrv_vmid always on)
  [2] RAMPOVRUPD wo — PA Analog Ramp Override Update Pulse
  [1] RAMPOVREN — PA Analog Ramp Override
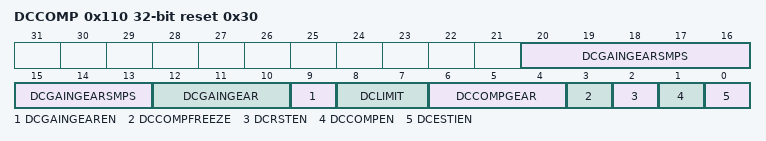
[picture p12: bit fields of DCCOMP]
0x110 DCCOMP reset 0x30
  [20:13] DCGAINGEARSMPS — DC Offset Gain Change Samples
  [12:10] DCGAINGEAR — DC Offset Gain Change Filter Gear
  [9] DCGAINGEAREN — DC Offset Gain Change Filter Gear Enable
  [8:7] DCLIMIT — DC offset limit
    0=FULLSCALE (1000 mV); 1=FULLSCALEBY4 (250 mV); 2=FULLSCALEBY8 (125 mV); 3=FULLSCALEBY16 (62 mV)
  [6:4] DCCOMPGEAR — DC Offset Compensation Filter Gear
  [3] DCCOMPFREEZE — DC Offset Compensation Filter Freeze
  [2] DCRSTEN — DC Compensation Filter Reset Enable
  [1] DCCOMPEN — DC Offset Compensation Enable
  [0] DCESTIEN — DC Offset Estimation Enable
